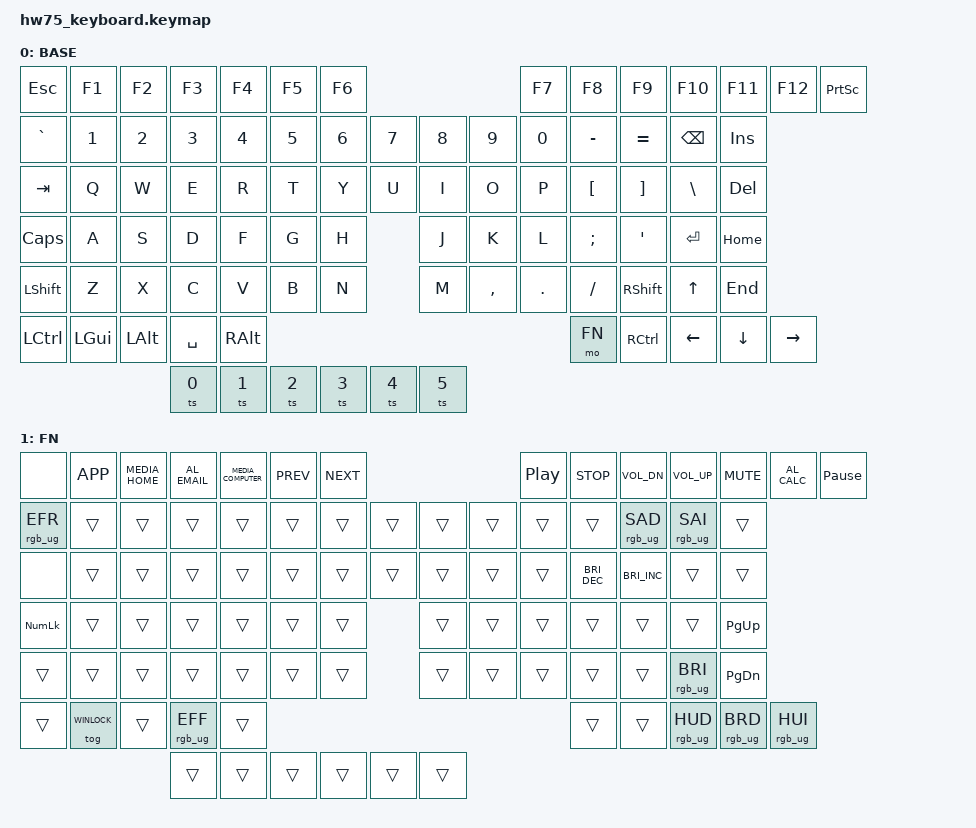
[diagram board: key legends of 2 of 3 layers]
/*
 * Copyright (c) 2022 The ZMK Contributors
 * SPDX-License-Identifier: MIT
 */

#include <behaviors.dtsi>
#include <behaviors/touch_strip.dtsi>
#include <dt-bindings/zmk/keys.h>
#include <dt-bindings/zmk/rgb.h>

#define BASE 0
#define FN 1
#define WINLOCK 2

/ {
    keymap {
        compatible = "zmk,keymap";

        base {
            label = "BASE";
            bindings = <
&kp ESC              &kp F1    &kp F2  &kp F3     &kp F4                &kp F5     &kp F6  &kp F7     &kp F8               &kp F9     &kp F10   &kp F11   &kp F12              &kp PRINTSCREEN
&kp GRAVE  &kp N1    &kp N2    &kp N3  &kp N4     &kp N5     &kp N6     &kp N7     &kp N8  &kp N9     &kp N0    &kp MINUS  &kp EQUAL  &kp BSPC                                 &kp INSERT
&kp TAB              &kp Q     &kp W   &kp E      &kp R      &kp T      &kp Y      &kp U   &kp I      &kp O     &kp P      &kp LBKT   &kp RBKT  &kp BSLH                       &kp DELETE
&kp CLCK             &kp A     &kp S   &kp D      &kp F      &kp G      &kp H      &kp J   &kp K      &kp L     &kp SEMI   &kp SQT              &kp RET                        &kp HOME
&kp LSHFT            &kp Z     &kp X   &kp C      &kp V      &kp B      &kp N      &kp M   &kp COMMA  &kp DOT   &kp FSLH   &kp RSHFT                      &kp UP               &kp END
&kp LCTRL  &kp LGUI  &kp LALT                                &kp SPACE                                &kp RALT  &mo FN     &kp RCTRL            &kp LEFT  &kp DOWN  &kp RIGHT
                               &ts 0  &ts 1  &ts 2  &ts 3  &ts 4  &ts 5
            >;
        };

        fn {
            label = "FN";
            bindings = <
&none                    &kp K_APP        &kp C_MEDIA_HOME &kp C_AL_EMAIL   &kp C_MEDIA_COMPUTER              &kp C_PREV  &kp C_NEXT  &kp C_PP    &kp C_STOP       &kp C_VOL_DN  &kp C_VOL_UP  &kp C_MUTE  &kp C_AL_CALC       &kp PAUSE_BREAK
&rgb_ug RGB_EFR  &trans  &trans           &trans           &trans           &trans           &trans           &trans  &trans  &trans      &trans    &trans  &rgb_ug RGB_SAD  &rgb_ug RGB_SAI                                &trans
&none                    &trans           &trans           &trans           &trans           &trans           &trans  &trans  &trans      &trans    &trans  &kp C_BRI_DEC  &kp C_BRI_INC  &trans                              &trans
&kp KP_NUMLOCK           &trans           &trans           &trans           &trans           &trans           &trans  &trans  &trans      &trans    &trans  &trans                  &trans                              &kp PG_UP
&trans                   &trans           &trans           &trans           &trans           &trans           &trans  &trans  &trans      &trans    &trans  &trans                                &rgb_ug RGB_BRI              &kp PG_DN
&trans           &tog WINLOCK   &trans                                                              &rgb_ug RGB_EFF                                &trans    &trans  &trans                  &rgb_ug RGB_HUD  &rgb_ug RGB_BRD  &rgb_ug RGB_HUI
                                          &trans           &trans           &trans           &trans           &trans  &trans
            >;
        };

        winlock {
            label = "WINLOCK";
            bindings = <
&trans              &trans   &trans &trans    &trans               &trans    &trans &trans    &trans              &trans    &trans    &trans    &trans               &trans
&trans     &trans   &trans   &trans &trans    &trans    &trans    &trans    &trans &trans    &trans   &trans    &trans    &trans                                 &trans
&trans               &trans  &trans &trans    &trans    &trans    &trans    &trans &trans    &trans   &trans    &trans    &trans                        &trans
&trans              &trans   &trans &trans    &trans    &trans    &trans    &trans &trans    &trans   &trans             &trans                         &trans
&trans             &trans   &trans &trans    &trans    &trans    &trans    &trans &trans    &trans   &trans    &trans                       &trans              &trans
&trans     &none    &trans                                 &trans                                 &trans   &tog WINLOCK &trans           &trans   &trans   &trans
                               &trans  &trans    &trans    &trans    &trans   &trans
            >;
        };
    };
};
